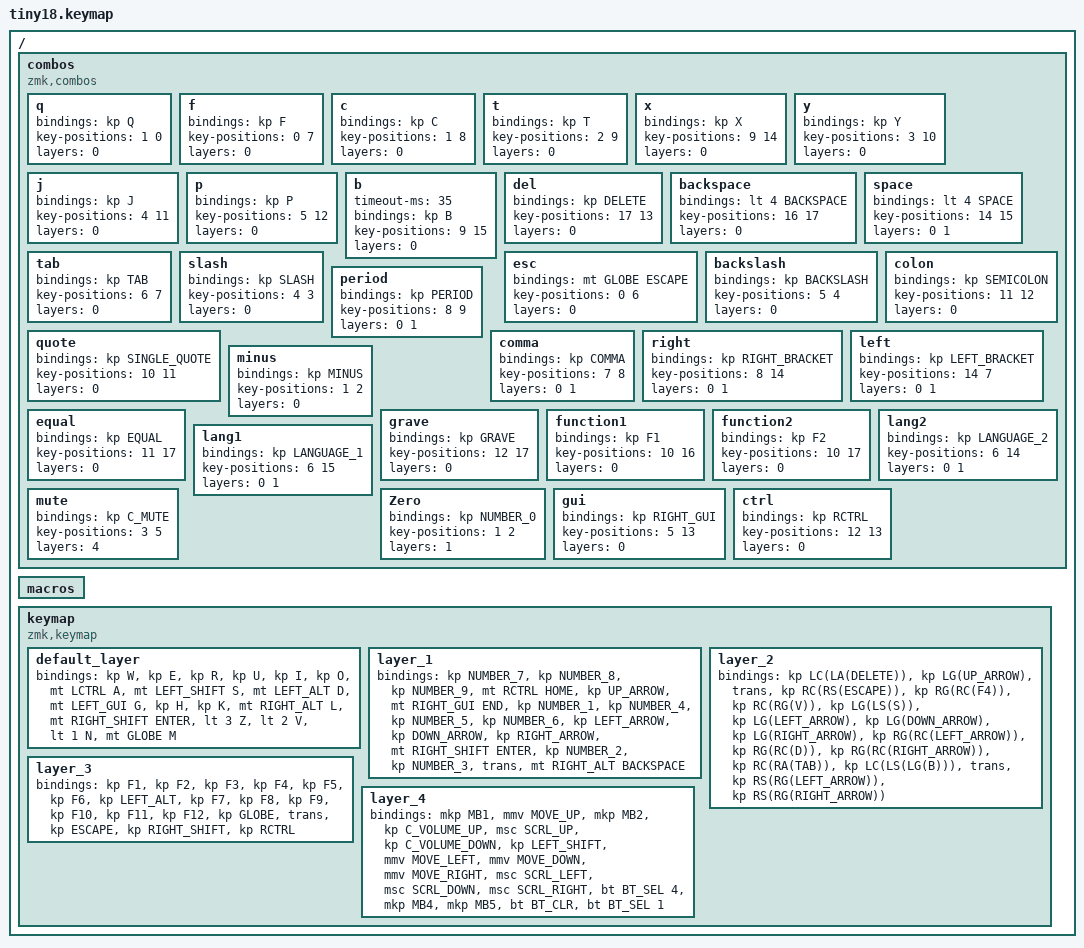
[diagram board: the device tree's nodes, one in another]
#include <input/processors.dtsi>
#include <dt-bindings/zmk/input_transform.h>
#include <zephyr/dt-bindings/input/input-event-codes.h>
#include <behaviors.dtsi>
#include <dt-bindings/zmk/bt.h>
#include <dt-bindings/zmk/keys.h>
#include <dt-bindings/zmk/pointing.h>

/ {
    combos {
        compatible = "zmk,combos";

        q {
            bindings = <&kp Q>;
            key-positions = <1 0>;
            layers = <0>;
        };

        f {
            bindings = <&kp F>;
            key-positions = <0 7>;
            layers = <0>;
        };

        c {
            bindings = <&kp C>;
            key-positions = <1 8>;
            layers = <0>;
        };

        t {
            bindings = <&kp T>;
            key-positions = <2 9>;
            layers = <0>;
        };

        x {
            bindings = <&kp X>;
            key-positions = <9 14>;
            layers = <0>;
        };

        y {
            bindings = <&kp Y>;
            key-positions = <3 10>;
            layers = <0>;
        };

        j {
            bindings = <&kp J>;
            key-positions = <4 11>;
            layers = <0>;
        };

        p {
            bindings = <&kp P>;
            key-positions = <5 12>;
            layers = <0>;
        };

        b {
            timeout-ms = <35>;
            bindings = <&kp B>;
            key-positions = <9 15>;
            layers = <0>;
        };

        del {
            bindings = <&kp DELETE>;
            key-positions = <17 13>;
            layers = <0>;
        };

        backspace {
            bindings = <&lt 4 BACKSPACE>;
            key-positions = <16 17>;
            layers = <0>;
        };

        space {
            bindings = <&lt 4 SPACE>;
            key-positions = <14 15>;
            layers = <0 1>;
        };

        tab {
            bindings = <&kp TAB>;
            key-positions = <6 7>;
            layers = <0>;
        };

        esc {
            bindings = <&mt GLOBE ESCAPE>;
            key-positions = <0 6>;
            layers = <0>;
        };

        backslash {
            bindings = <&kp BACKSLASH>;
            key-positions = <5 4>;
            layers = <0>;
        };

        slash {
            bindings = <&kp SLASH>;
            key-positions = <4 3>;
            layers = <0>;
        };

        colon {
            bindings = <&kp SEMICOLON>;
            key-positions = <11 12>;
            layers = <0>;
        };

        quote {
            bindings = <&kp SINGLE_QUOTE>;
            key-positions = <10 11>;
            layers = <0>;
        };

        period {
            bindings = <&kp PERIOD>;
            key-positions = <8 9>;
            layers = <0 1>;
        };

        comma {
            bindings = <&kp COMMA>;
            key-positions = <7 8>;
            layers = <0 1>;
        };

        right {
            bindings = <&kp RIGHT_BRACKET>;
            key-positions = <8 14>;
            layers = <0 1>;
        };

        left {
            bindings = <&kp LEFT_BRACKET>;
            key-positions = <14 7>;
            layers = <0 1>;
        };

        minus {
            bindings = <&kp MINUS>;
            key-positions = <1 2>;
            layers = <0>;
        };

        equal {
            bindings = <&kp EQUAL>;
            key-positions = <11 17>;
            layers = <0>;
        };

        grave {
            bindings = <&kp GRAVE>;
            key-positions = <12 17>;
            layers = <0>;
        };

        function1 {
            bindings = <&kp F1>;
            key-positions = <10 16>;
            layers = <0>;
        };

        function2 {
            bindings = <&kp F2>;
            key-positions = <10 17>;
            layers = <0>;
        };

        lang2 {
            bindings = <&kp LANGUAGE_2>;
            key-positions = <6 14>;
            layers = <0 1>;
        };

        lang1 {
            bindings = <&kp LANGUAGE_1>;
            key-positions = <6 15>;
            layers = <0 1>;
        };

        Zero {
            bindings = <&kp NUMBER_0>;
            key-positions = <1 2>;
            layers = <1>;
        };

        mute {
            bindings = <&kp C_MUTE>;
            key-positions = <3 5>;
            layers = <4>;
        };

        gui {
            bindings = <&kp RIGHT_GUI>;
            key-positions = <5 13>;
            layers = <0>;
        };

        ctrl {
            bindings = <&kp RCTRL>;
            key-positions = <12 13>;
            layers = <0>;
        };
    };

    macros {
        // iPad接続用（プロファイル0を選択し、レイヤー1へ移動）
        // iPhone接続用（プロファイル1を選択し、レイヤー1へ移動）
    };

    keymap {
        compatible = "zmk,keymap";

        default_layer {
            bindings = <
&kp W  &kp E  &kp R  &kp U  &kp I  &kp O  &mt LCTRL A  &mt LEFT_SHIFT S  &mt LEFT_ALT D  &mt LEFT_GUI G  &kp H  &kp K  &mt RIGHT_ALT L  &mt RIGHT_SHIFT ENTER  &lt 3 Z  &lt 2 V  &lt 1 N  &mt GLOBE M
            >;
        };

        layer_1 {
            bindings = <
&kp NUMBER_7  &kp NUMBER_8  &kp NUMBER_9  &mt RCTRL HOME  &kp UP_ARROW  &mt RIGHT_GUI END  &kp NUMBER_1  &kp NUMBER_4  &kp NUMBER_5  &kp NUMBER_6  &kp LEFT_ARROW  &kp DOWN_ARROW  &kp RIGHT_ARROW  &mt RIGHT_SHIFT ENTER  &kp NUMBER_2  &kp NUMBER_3  &trans  &mt RIGHT_ALT BACKSPACE
            >;
        };

        layer_2 {
            bindings = <
&kp LC(LA(DELETE))  &kp LG(UP_ARROW)  &trans  &kp RC(RS(ESCAPE))  &kp RG(RC(F4))  &kp RC(RG(V))  &kp LG(LS(S))  &kp LG(LEFT_ARROW)  &kp LG(DOWN_ARROW)  &kp LG(RIGHT_ARROW)  &kp RG(RC(LEFT_ARROW))  &kp RG(RC(D))  &kp RG(RC(RIGHT_ARROW))  &kp RC(RA(TAB))  &kp LC(LS(LG(B)))  &trans  &kp RS(RG(LEFT_ARROW))  &kp RS(RG(RIGHT_ARROW))
            >;
        };

        layer_3 {
            bindings = <
&kp F1  &kp F2  &kp F3  &kp F4  &kp F5  &kp F6  &kp LEFT_ALT  &kp F7  &kp F8  &kp F9  &kp F10  &kp F11  &kp F12  &kp GLOBE  &trans  &kp ESCAPE  &kp RIGHT_SHIFT  &kp RCTRL
            >;
        };

        layer_4 {
            bindings = <
&mkp MB1  &mmv MOVE_UP  &mkp MB2  &kp C_VOLUME_UP  &msc SCRL_UP  &kp C_VOLUME_DOWN  &kp LEFT_SHIFT  &mmv MOVE_LEFT  &mmv MOVE_DOWN  &mmv MOVE_RIGHT  &msc SCRL_LEFT  &msc SCRL_DOWN  &msc SCRL_RIGHT  &bt BT_SEL 4  &mkp MB4  &mkp MB5  &bt BT_CLR  &bt BT_SEL 1
            >;
        };
    };
};
